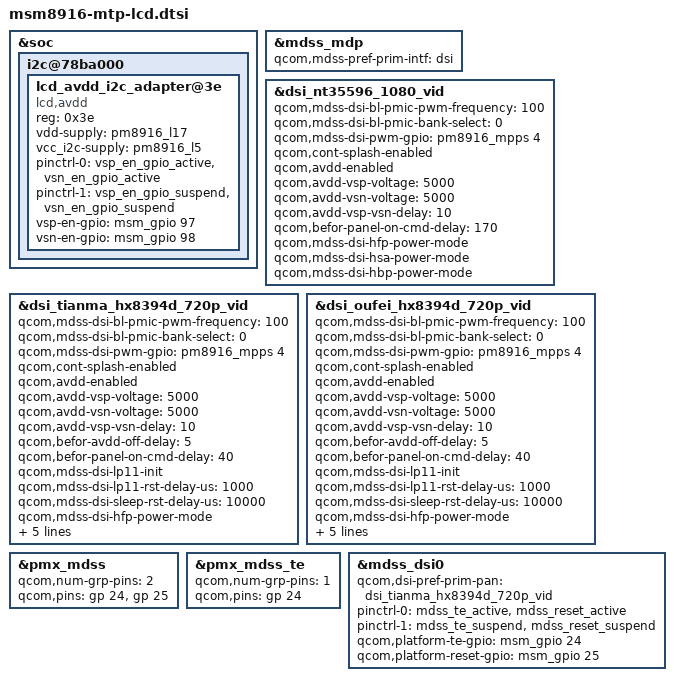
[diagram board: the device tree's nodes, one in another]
/* Copyright (c) 2014, The Linux Foundation. All rights reserved.
 *
 * This program is free software; you can redistribute it and/or modify
 * it under the terms of the GNU General Public License version 2 and
 * only version 2 as published by the Free Software Foundation.
 *
 * This program is distributed in the hope that it will be useful,
 * but WITHOUT ANY WARRANTY; without even the implied warranty of
 * MERCHANTABILITY or FITNESS FOR A PARTICULAR PURPOSE.  See the
 * GNU General Public License for more details.
 */

#include "msm8916-lcd-pinctrl.dtsi"
#include "dsi-sharp-panel-nt35596-1080p-video.dtsi"
#include "dsi-tianma-panel-hx8394d-720p-video.dtsi"
#include "dsi-oufei-panel-hx8394d-720p-video.dtsi"

&soc {
	i2c@78ba000 { /* BLSP1 QUP6 */
		lcd_avdd_i2c_adapter@3e {
			compatible = "lcd,avdd";
			reg = <0x3e>;
			vdd-supply = <&pm8916_l17>;
			vcc_i2c-supply = <&pm8916_l5>;
			pinctrl-0 = <&vsp_en_gpio_active &vsn_en_gpio_active>;
			pinctrl-1 = <&vsp_en_gpio_suspend &vsn_en_gpio_suspend>;
			vsp-en-gpio    = <&msm_gpio 97 0x00>;
			vsn-en-gpio    = <&msm_gpio 98 0x00>;
		};
	};
};

&mdss_mdp {
	qcom,mdss-pref-prim-intf = "dsi";
};

&dsi_nt35596_1080_vid {
	qcom,mdss-dsi-bl-pmic-pwm-frequency = <100>;
	qcom,mdss-dsi-bl-pmic-bank-select = <0>;
	qcom,mdss-dsi-pwm-gpio = <&pm8916_mpps 4 0>;
    qcom,cont-splash-enabled;
    qcom,avdd-enabled;
    qcom,avdd-vsp-voltage = <5000>;
    qcom,avdd-vsn-voltage = <5000>;
    qcom,avdd-vsp-vsn-delay = <10>;
    qcom,befor-panel-on-cmd-delay = <170>;

    //LP11
	qcom,mdss-dsi-hfp-power-mode;
	qcom,mdss-dsi-hsa-power-mode;
	qcom,mdss-dsi-hbp-power-mode;

	//ESD check enable
	//qcom,esd-check-enabled;

	//ESD check method choice and only choose one
	//qcom,mdss-dsi-panel-status-check-mode = "bta_check";
	//qcom,mdss-dsi-panel-status-check-mode = "reg_read_zte";
};

&dsi_tianma_hx8394d_720p_vid {
	qcom,mdss-dsi-bl-pmic-pwm-frequency = <100>;
	qcom,mdss-dsi-bl-pmic-bank-select = <0>;
	qcom,mdss-dsi-pwm-gpio = <&pm8916_mpps 4 0>;
	qcom,cont-splash-enabled;

    //avdd 
    qcom,avdd-enabled;
    qcom,avdd-vsp-voltage = <5000>;
    qcom,avdd-vsn-voltage = <5000>;

	//timing
    qcom,avdd-vsp-vsn-delay = <10>;
    qcom,befor-avdd-off-delay 	= <5>;
    qcom,befor-panel-on-cmd-delay = <40>;
	qcom,mdss-dsi-lp11-init;
	qcom,mdss-dsi-lp11-rst-delay-us = <1000>;
	qcom,mdss-dsi-sleep-rst-delay-us  = <10000>;

    //LP11
	qcom,mdss-dsi-hfp-power-mode;
	qcom,mdss-dsi-hsa-power-mode;
	qcom,mdss-dsi-hbp-power-mode;

	//ESD check
	qcom,esd-check-enabled;
	//ESD check method choice and only choose one
	qcom,mdss-dsi-panel-status-check-mode = "bta_check";
	//qcom,mdss-dsi-panel-status-check-mode = "reg_read_zte";
};

&dsi_oufei_hx8394d_720p_vid {
	qcom,mdss-dsi-bl-pmic-pwm-frequency = <100>;
	qcom,mdss-dsi-bl-pmic-bank-select = <0>;
	qcom,mdss-dsi-pwm-gpio = <&pm8916_mpps 4 0>;
    qcom,cont-splash-enabled;

    //avdd 
    qcom,avdd-enabled;
    qcom,avdd-vsp-voltage = <5000>;
    qcom,avdd-vsn-voltage = <5000>;

	//timing
    qcom,avdd-vsp-vsn-delay = <10>;
    qcom,befor-avdd-off-delay 	= <5>;
    qcom,befor-panel-on-cmd-delay = <40>;
	qcom,mdss-dsi-lp11-init;
	qcom,mdss-dsi-lp11-rst-delay-us = <1000>;
	qcom,mdss-dsi-sleep-rst-delay-us  = <10000>;

    //LP11
	qcom,mdss-dsi-hfp-power-mode;
	qcom,mdss-dsi-hsa-power-mode;
	qcom,mdss-dsi-hbp-power-mode;

	//ESD check
	qcom,esd-check-enabled;
	//ESD check method choice and only choose one
	qcom,mdss-dsi-panel-status-check-mode = "bta_check";
	//qcom,mdss-dsi-panel-status-check-mode = "reg_read_zte";
};

&pmx_mdss {
	qcom,num-grp-pins = <2>;
	qcom,pins = <&gp 24>, <&gp 25>;
};

&pmx_mdss_te {
	qcom,num-grp-pins = <1>;
	qcom,pins = <&gp 24>;
};

&mdss_dsi0 {
	qcom,dsi-pref-prim-pan = <&dsi_tianma_hx8394d_720p_vid>;
	pinctrl-names = "mdss_default", "mdss_sleep";
	pinctrl-0 = <&mdss_te_active &mdss_reset_active>;
	pinctrl-1 = <&mdss_te_suspend &mdss_reset_suspend>;

	qcom,platform-te-gpio = <&msm_gpio 24 0>;
	qcom,platform-reset-gpio = <&msm_gpio 25 0>;
};
